# AE8SUPERSET_CM55_HE_View register map
Vendor: Alif Semiconductor; Series: E8; File version: 1.0
CPU: CM55 r1p0, selectable endian, MPU, FPU, double-precision FPU, DSP, VTOR, 8 interrupt priority bits, 1 SAU regions
Registers are 32-bit, read-write, reset 0x0 unless marked. A register's access mark holds for its fields unless they carry their own. Offsets are from the block's base; [hi:lo] are bit positions; lines under a group give offsets from that group; {n}, {i} and the like mark numbered series; 'fields as' and 'values as' point back to an identical list.

## LPUTIMER
Base 0x4300C000
Same registers: UTIMER 0x48000000
0x00 UTIMER_GLB_CNTR_START — Channels Global Counter Start Register
  [15:0] CHANNEL_NUM wo — Write 1 to start the associated channel counter.
0x04 UTIMER_GLB_CNTR_STOP — Channels Global Counter Stop Register
  [15:0] CHANNEL_NUM wo — Write 1 to stop the associated channel counter.
0x08 UTIMER_GLB_CNTR_CLEAR — Channels Global Counter Clear Register
  [15:0] CHANNEL_NUM wo — Write 1 to clear the associated channel counter.
0x0C UTIMER_GLB_CNTR_RUNNING ro — Channels Global Counter Running Status Register
  [15:0] CHANNEL_NUM — Real-time running status of each channel.
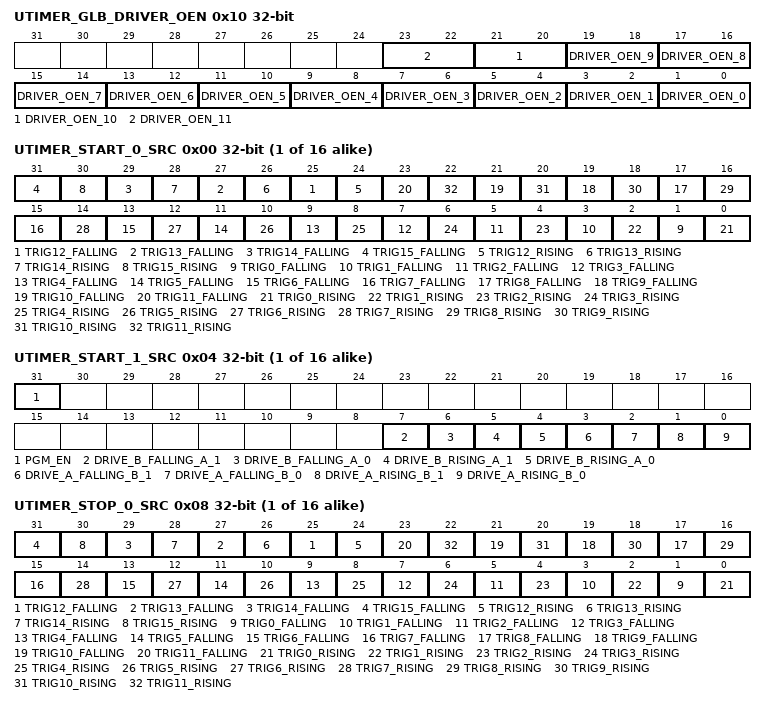
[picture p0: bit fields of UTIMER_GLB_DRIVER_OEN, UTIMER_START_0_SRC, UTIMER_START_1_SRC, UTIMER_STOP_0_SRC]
0x10 UTIMER_GLB_DRIVER_OEN — Channels Driver Output Enable Register
  [2n+1:2n] DRIVER_OEN_{n} (n=0..11) — Channel {n} active low output enable controls for driver A and B. B is the upper bit, A is the lower bit.
0x20 UTIMER_GLB_CLOCK_ENABLE — Channels Clock Enable Register
  [15:0] CHANNEL_NUM — Clock control for each channel.
{0x1000+0x1000*i} UTIMER_CHANNEL_CFG[{i}] (i=0..15) group
  0x00 UTIMER_START_0_SRC — Channel (n) Counter Start Source 0 Register
    [2n+1] TRIG{n}_FALLING (n=12..15) — For UTIMER channels: Falling edge of global trigger {n} causes counter to start. For QEC channels: Reserved, not used.
    [2n] TRIG{n}_RISING (n=12..15) — For UTIMER channels: Rising edge of global trigger {n} causes counter to start. For QEC channels: Reserved, not used.
    [2n+1] TRIG{n}_FALLING (n=0..11) — For UTIMER channels: Falling edge of global trigger {n} causes counter to start. For QEC channels: Falling edge of QEC_TRIGGER{n} causes counter to start.
    [2n] TRIG{n}_RISING (n=0..11) — For UTIMER channels: Rising edge of global trigger {n} causes counter to start. For QEC channels: Rising edge of QEC_TRIGGER{n} causes counter to start.
  0x04 UTIMER_START_1_SRC — Channel (n) Counter Start Source 1 Register
    [31] PGM_EN — Programatic Start Enabled:
      0=Global programmatic start is disabled; 1=Global programmatic start is enabled (only for start, stop, and clear)
    [7] DRIVE_B_FALLING_A_1 — For this channel, channel input B is falling and channel input A = 1 causes counter to start.
    [6] DRIVE_B_FALLING_A_0 — For this channel, channel input B is falling and channel input A = 0 causes counter to start.
    [5] DRIVE_B_RISING_A_1 — For this channel, channel input B is rising and channel input A = 1 causes counter to start.
    [4] DRIVE_B_RISING_A_0 — For this channel, channel input B is rising and channel input A = 0 causes counter to start.
    [3] DRIVE_A_FALLING_B_1 — For this channel, channel input A is falling and channel input B = 1 causes counter to start.
    [2] DRIVE_A_FALLING_B_0 — For this channel, channel input A is falling and channel input B = 0 causes counter to start.
    [1] DRIVE_A_RISING_B_1 — For this channel, channel input A is rising and channel input B = 1 causes counter to start.
    [0] DRIVE_A_RISING_B_0 — For this channel, channel input A is rising and channel input B = 0 causes counter to start.
  0x08 UTIMER_STOP_0_SRC — Channel (n) Counter Stop Source 0 Register
    [2n+1] TRIG{n}_FALLING (n=12..15) — For UTIMER channels: Falling edge of global trigger {n} causes counter to stop. For QEC channels: Reserved, not used.
    [2n] TRIG{n}_RISING (n=12..15) — For UTIMER channels: Rising edge of global trigger {n} causes counter to stop. For QEC channels: Reserved, not used.
    [2n+1] TRIG{n}_FALLING (n=0..11) — For UTIMER channels: Falling edge of global trigger {n} causes counter to stop. For QEC channels: Falling edge of QEC_TRIGGER{n} causes counter to stop.
    [2n] TRIG{n}_RISING (n=0..11) — For UTIMER channels: Rising edge of global trigger {n} causes counter to stop. For QEC channels: Rising edge of QEC_TRIGGER{n} causes counter to stop.
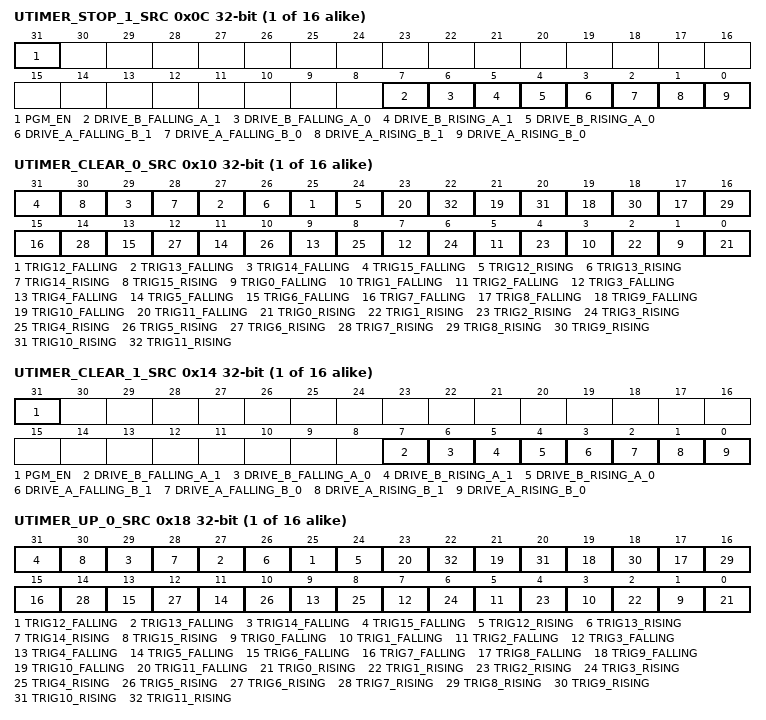
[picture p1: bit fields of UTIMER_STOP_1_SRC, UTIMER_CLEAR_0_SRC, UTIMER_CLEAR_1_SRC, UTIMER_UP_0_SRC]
  0x0C UTIMER_STOP_1_SRC — Channel (n) Counter Stop Source 1 Register
    [31] PGM_EN — Programatic Stop Enabled:
      0=Global programmatic stop is disabled; 1=Global programmatic stop is enabled (only for start, stop, and clear)
    [7] DRIVE_B_FALLING_A_1 — For this channel, channel input B is falling and channel input A = 1 causes counter to stop.
    [6] DRIVE_B_FALLING_A_0 — For this channel, channel input B is falling and channel input A = 0 causes counter to stop.
    [5] DRIVE_B_RISING_A_1 — For this channel, channel input B is rising and channel input A = 1 causes counter to stop.
    [4] DRIVE_B_RISING_A_0 — For this channel, channel input B is rising and channel input A = 0 causes counter to stop.
    [3] DRIVE_A_FALLING_B_1 — For this channel, channel input A is falling and channel input B = 1 causes counter to stop.
    [2] DRIVE_A_FALLING_B_0 — For this channel, channel input A is falling and channel input B = 0 causes counter to stop.
    [1] DRIVE_A_RISING_B_1 — For this channel, channel input A is rising and channel input B = 1 causes counter to stop.
    [0] DRIVE_A_RISING_B_0 — For this channel, channel input A is rising and channel input B = 0 causes counter to stop.
  0x10 UTIMER_CLEAR_0_SRC — Channel (n) Counter Clear Source 0 Register
    [2n+1] TRIG{n}_FALLING (n=12..15) — For UTIMER channels: Falling edge of global trigger {n} causes counter to clear. For QEC channels: Reserved, not used.
    [2n] TRIG{n}_RISING (n=12..15) — For UTIMER channels: Rising edge of global trigger {n} causes counter to clear. For QEC channels: Reserved, not used.
    [2n+1] TRIG{n}_FALLING (n=0..11) — For UTIMER channels: Falling edge of global trigger {n} causes counter to clear. For QEC channels: Falling edge of QEC_TRIGGER{n} causes counter to clear.
    [2n] TRIG{n}_RISING (n=0..11) — For UTIMER channels: Rising edge of global trigger {n} causes counter to clear. For QEC channels: Rising edge of QEC_TRIGGER{n} causes counter to clear.
  0x14 UTIMER_CLEAR_1_SRC — Channel (n) Counter Clear Source 1 Register
    [31] PGM_EN — Programmatic Clear Enabled:
      0=Global programmatic clear is disabled; 1=Global programmatic clear is enabled (only for start, stop, and clear)
    [7] DRIVE_B_FALLING_A_1 — For this channel, channel input B is falling and channel input A = 1 causes counter to clear.
    [6] DRIVE_B_FALLING_A_0 — For this channel, channel input B is falling and channel input A = 0 causes counter to clear.
    [5] DRIVE_B_RISING_A_1 — For this channel, channel input B is rising and channel input A = 1 causes counter to clear.
    [4] DRIVE_B_RISING_A_0 — For this channel, channel input B is rising and channel input A = 0 causes counter to clear.
    [3] DRIVE_A_FALLING_B_1 — For this channel, channel input A is falling and channel input B = 1 causes counter to clear.
    [2] DRIVE_A_FALLING_B_0 — For this channel, channel input A is falling and channel input B = 0 causes counter to clear.
    [1] DRIVE_A_RISING_B_1 — For this channel, channel input A is rising and channel input B = 1 causes counter to clear.
    [0] DRIVE_A_RISING_B_0 — For this channel, channel input A is rising and channel input B = 0 causes counter to clear.
  0x18 UTIMER_UP_0_SRC — Channel (n) Counter Up Count Source 0 Register
    [2n+1] TRIG{n}_FALLING (n=12..15) — For UTIMER channels: Falling edge of global trigger {n} causes counter to increment. For QEC channels: Reserved, not used.
    [2n] TRIG{n}_RISING (n=12..15) — For UTIMER channels: Rising edge of global trigger {n} causes counter to increment. For QEC channels: Reserved, not used.
    [2n+1] TRIG{n}_FALLING (n=0..11) — For UTIMER channels: Falling edge of global trigger {n} causes counter to increment. For QEC channels: Falling edge of QEC_TRIGGER{n} causes counter to increment.
    [2n] TRIG{n}_RISING (n=0..11) — For UTIMER channels: Rising edge of global trigger {n} causes counter to increment. For QEC channels: Rising edge of QEC_TRIGGER{n} causes counter to increment.
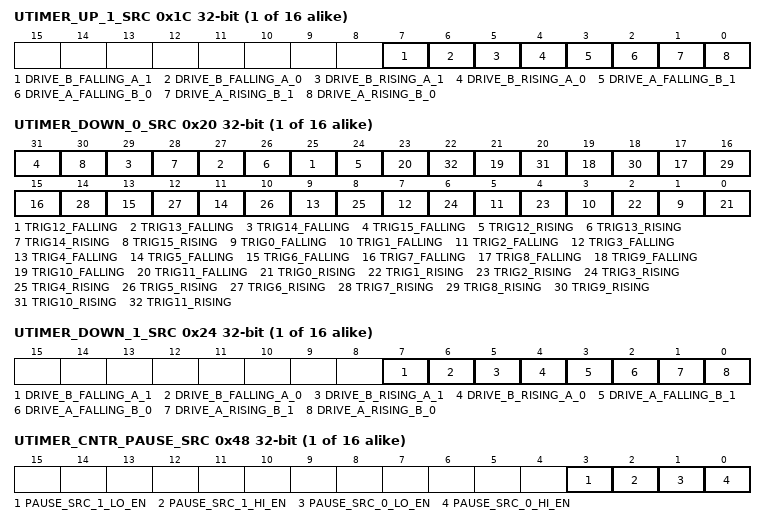
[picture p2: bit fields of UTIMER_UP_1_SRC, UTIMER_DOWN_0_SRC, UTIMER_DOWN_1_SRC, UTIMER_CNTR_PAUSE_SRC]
  0x1C UTIMER_UP_1_SRC — Channel (n) Counter Up Count Source 1 Register
    [7] DRIVE_B_FALLING_A_1 — For this channel, channel input B is falling and channel input A = 1 causes counter to increment.
    [6] DRIVE_B_FALLING_A_0 — For this channel, channel input B is falling and channel input A = 0 causes counter to increment.
    [5] DRIVE_B_RISING_A_1 — For this channel, channel input B is rising and channel input A = 1 causes counter to increment.
    [4] DRIVE_B_RISING_A_0 — For this channel, channel input B is rising and channel input A = 0 causes counter to increment.
    [3] DRIVE_A_FALLING_B_1 — For this channel, channel input A is falling and channel input B = 1 causes counter to increment.
    [2] DRIVE_A_FALLING_B_0 — For this channel, channel input A is falling and channel input B = 0 causes counter to increment.
    [1] DRIVE_A_RISING_B_1 — For this channel, channel input A is rising and channel input B = 1 causes counter to increment.
    [0] DRIVE_A_RISING_B_0 — For this channel, channel input A is rising and channel input B = 0 causes counter to increment.
  0x20 UTIMER_DOWN_0_SRC — Channel (n) Counter Down Count Source 0 Register
    [2n+1] TRIG{n}_FALLING (n=12..15) — For UTIMER channels: Falling edge of global trigger {n} causes counter to decrement. For QEC channels: Reserved, not used.
    [2n] TRIG{n}_RISING (n=12..15) — For UTIMER channels: Rising edge of global trigger {n} causes counter to decrement. For QEC channels: Reserved, not used.
    [2n+1] TRIG{n}_FALLING (n=0..11) — For UTIMER channels: Falling edge of global trigger {n} causes counter to decrement. For QEC channels: Falling edge of QEC_TRIGGER{n} causes counter to decrement.
    [2n] TRIG{n}_RISING (n=0..11) — For UTIMER channels: Rising edge of global trigger {n} causes counter to decrement. For QEC channels: Rising edge of QEC_TRIGGER{n} causes counter to decrement.
  0x24 UTIMER_DOWN_1_SRC — Channel (n) Counter Down Count Source 1 Register
    [7] DRIVE_B_FALLING_A_1 — For this channel, channel input B is falling and channel input A = 1 causes counter to decrement.
    [6] DRIVE_B_FALLING_A_0 — For this channel, channel input B is falling and channel input A = 0 causes counter to decrement.
    [5] DRIVE_B_RISING_A_1 — For this channel, channel input B is rising and channel input A = 1 causes counter to decrement.
    [4] DRIVE_B_RISING_A_0 — For this channel, channel input B is rising and channel input A = 0 causes counter to decrement.
    [3] DRIVE_A_FALLING_B_1 — For this channel, channel input A is falling and channel input B = 1 causes counter to decrement.
    [2] DRIVE_A_FALLING_B_0 — For this channel, channel input A is falling and channel input B = 0 causes counter to decrement.
    [1] DRIVE_A_RISING_B_1 — For this channel, channel input A is rising and channel input B = 1 causes counter to decrement.
    [0] DRIVE_A_RISING_B_0 — For this channel, channel input A is rising and channel input B = 0 causes counter to decrement.
  0x28 UTIMER_TRIG_CAPTURE_SRC_A_0 — Channel (n) Trigger Capture Source A 0 Register
    [31:0] TRIG_CAPTURE_SRC_A — Capture the counter value, when channel input A is the source (decoding is the same as in the UTIMERn_START_0_SRC register).
  0x2C UTIMER_TRIG_CAPTURE_SRC_A_1 — Channel (n) Trigger Capture Source A 1 Register
    [31:0] TRIG_CAPTURE_SRC_A — Capture the counter value, when channel input A is the source (decoding is the same as in the UTIMERn_START_1_SRC register).
  0x30 UTIMER_TRIG_CAPTURE_SRC_B_0 — Channel (n) Trigger Capture Source B 0 Register
    [31:0] TRIG_CAPTURE_SRC_B — Capture the counter value, when channel input B is the source (decoding is the same as in the UTIMERn_START_0_SRC register).
  0x34 UTIMER_TRIG_CAPTURE_SRC_B_1 — Channel (n) Trigger Capture Source B 1 Register
    [31:0] TRIG_CAPTURE_SRC_B — Capture the counter value, when channel input A is the source (decoding is the same as in the UTIMERn_START_1_SRC register).
  0x38 UTIMER_DMA_CLEAR_SRC_A_0 — Channel (n) DMA Clear Source A 0 Register
    [31:0] DMA_CLEAR_SRC_A — Clear DMA when driver A is the source (decoding is the same as in the UTIMERn_START_0_SRC register).
  0x3C UTIMER_DMA_CLEAR_SRC_A_1 — Channel (n) DMA Clear Source A 1 Register
    [31:0] DMA_CLEAR_SRC_A — Clear DMA when driver A is the source (decoding is the same as in the UTIMERn_START_1_SRC register).
  0x40 UTIMER_DMA_CLEAR_SRC_B_0 — Channel (n) DMA Clear Source B 0 Register
    [31:0] DMA_CLEAR_SRC_B — Clear DMA when driver B is the source (decoding is the same as in the UTIMERn_START_0_SRC register).
  0x44 UTIMER_DMA_CLEAR_SRC_B_1 — Channel (n) DMA Clear Source B 1 Register
    [31:0] DMA_CLEAR_SRC_B — Clear DMA when driver B is the source (decoding is the same as in the UTIMERn_START_1_SRC register).
  0x48 UTIMER_CNTR_PAUSE_SRC — Channel (n) Counter Pause Source Register
    [3] PAUSE_SRC_1_LO_EN — While PAUSE_TRIGGER[1] = 0x0, pause the channel counter.
    [2] PAUSE_SRC_1_HI_EN — While PAUSE_TRIGGER[1] = 0x1, pause the channel counter.
    [1] PAUSE_SRC_0_LO_EN — While PAUSE_TRIGGER[0] = 0x0, pause the channel counter.
    [0] PAUSE_SRC_0_HI_EN — While PAUSE_TRIGGER[0] = 0x1, pause the channel counter.
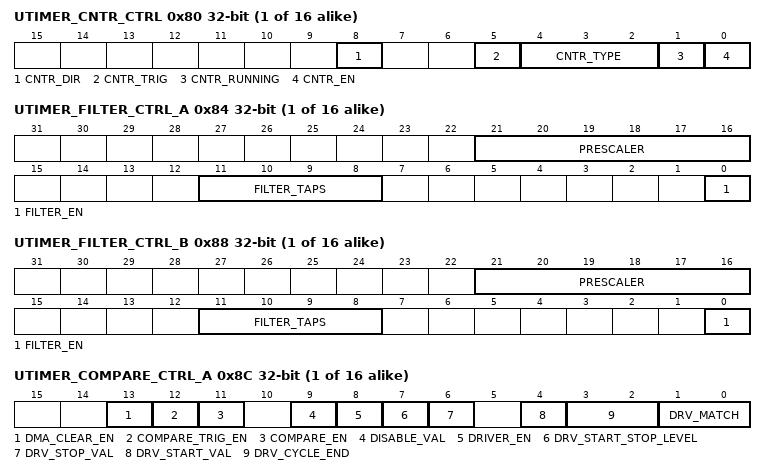
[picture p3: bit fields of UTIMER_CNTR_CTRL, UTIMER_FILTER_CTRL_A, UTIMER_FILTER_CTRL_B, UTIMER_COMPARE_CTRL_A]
  0x80 UTIMER_CNTR_CTRL — Channel (n) Counter Control Register
    [8] CNTR_DIR — Counter Direction: Note: For triangle counter, this will be the direction at a start event Note: If the direction is changed while the counter is running, it will take effect at the next over/underrun. Changes during triangle wave have no effect.
      0=Up; 1=Down
    [5] CNTR_TRIG — Set this bit if incrementing or decrementing the counter via triggers.
      0=Not in trigger based increment/decrement mode; 1=Trigger based increment/decrement mode
    [4:2] CNTR_TYPE — Counter Type:
      0=Sawtooth; 1=Sawtooth one shot; 4=Triangle; 6=Triangle one shot
    [1] CNTR_RUNNING — Counter Running: Note: Writing this bit have no effect.
      0=Count operation is stopped; 1=Count operation is running
    [0] CNTR_EN — Counter Enable:
      0=Counter is disabled; 1=Counter is enabled
  0x84 UTIMER_FILTER_CTRL_A — Channel (n) Filter Control A Register
    [21:16] PRESCALER — Prescaler function. Allows the input A to be sampled periodically according to the programmed value. For example, if programmed to 0x10, the input A is sampled every 16 clocks before entering the filter taps.
      0=Input A is sampled every clock before entering the filter taps; 1=Input A is sampled every clock before entering the filter taps; {v}=Input A is sampled periodically according to this value (v=2..63)
    [11:8] FILTER_TAPS — Number of filter taps.
    [0] FILTER_EN — Enable the filtering function.
  0x88 UTIMER_FILTER_CTRL_B — Channel (n) Filter Control B Register
    [21:16] PRESCALER — Prescaler function. Allows the input B to be sampled periodically according to the programmed value. For example, if programmed to 0x10, the input B is sampled every 16 clocks before entering the filter taps.
      0=Input B is sampled every clock before entering the filter taps; 1=Input B is sampled every clock before entering the filter taps; {v}=Input B is sampled periodically according to this value (v=2..63)
    [11:8] FILTER_TAPS — Number of filter taps.
    [0] FILTER_EN — Enable the filtering function.
  0x8C UTIMER_COMPARE_CTRL_A — Channel (n) Compare Control A Register
    [13] DMA_CLEAR_EN
      0=Disable DMA_CLEAR function; 1=Enable DMA_CLEAR function
    [12] COMPARE_TRIG_EN — Enable compare match for trigger input: Note: Only enable if desire compare function during trigger driven counting.
      0=Compare match when trigger count disabled; 1=Compare match when trigger count enabled
    [11] COMPARE_EN — Enable compare match:
      0=Compare match is disabled; 1=Compare match is enabled
    [9] DISABLE_VAL — Driver value when output is disabled via bit [8] of this register.
    [8] DRIVER_EN — Driver output enable.
      0=Driver output is disabled, will take value at bit [9] of this register; 1=Driver output is controlled by compare logic
    [7] DRV_START_STOP_LEVEL — Driver output level at start or stop:
      0=Driver output at start or stop reflects value at bit [4] and bit [6] of this register; 1=Driver output at start or stop is retained
    [6] DRV_STOP_VAL — Driver value when counting stops.
    [4] DRV_START_VAL — Driver value when counting starts.
    [3:2] DRV_CYCLE_END — Driver value at cycle end:
      0=Driver value retained at cycle end; 1=Driver value is 0x0 at cycle end; 2=Driver value is 0x1 at cycle end; 3=Driver value toggles at cycle end
    [1:0] DRV_MATCH — Driver A value at compare match:
      0=Driver value retained at compare match; 1=Driver value is 0x0 at compare match; 2=Driver value is 0x1 at compare match; 3=Driver value toggles at compare match
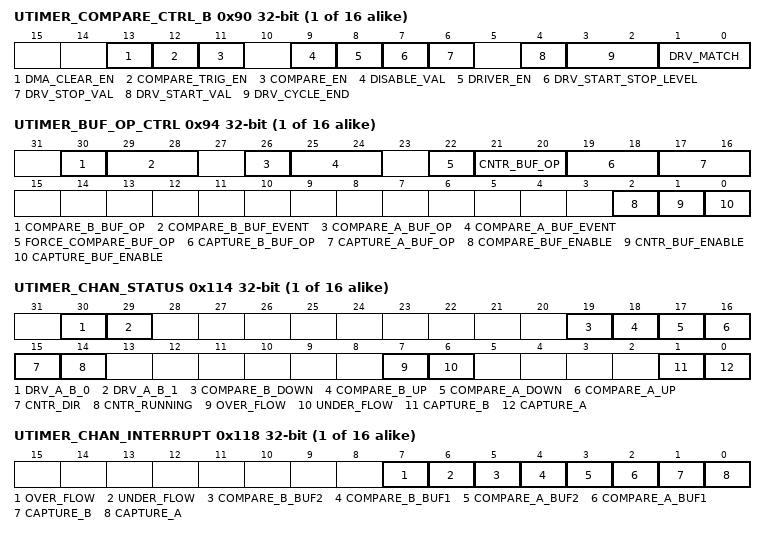
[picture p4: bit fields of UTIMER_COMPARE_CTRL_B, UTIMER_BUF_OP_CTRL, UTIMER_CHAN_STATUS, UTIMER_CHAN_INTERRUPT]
  0x90 UTIMER_COMPARE_CTRL_B — Channel (n) Compare Control B Register
    [13] DMA_CLEAR_EN
      0=Disable DMA_CLEAR function; 1=Enable DMA_CLEAR function
    [12] COMPARE_TRIG_EN — Enable compare match for trigger input: Note: Only enable if desire compare function during trigger driven counting.
      values as UTIMER_CHANNEL_CFG[0].UTIMER_COMPARE_CTRL_A.COMPARE_TRIG_EN
    [11] COMPARE_EN — Enable compare match:
      0=Compare match is disabled; 1=Compare match is enabled
    [9] DISABLE_VAL — Driver value when output is disabled via bit [8] of this register.
    [8] DRIVER_EN — Driver output enable.
      values as UTIMER_CHANNEL_CFG[0].UTIMER_COMPARE_CTRL_A.DRIVER_EN
    [7] DRV_START_STOP_LEVEL — Driver output level at start or stop:
      values as UTIMER_CHANNEL_CFG[0].UTIMER_COMPARE_CTRL_A.DRV_START_STOP_LEVEL
    [6] DRV_STOP_VAL — Driver value when counting stops.
    [4] DRV_START_VAL — Driver value when counting starts.
    [3:2] DRV_CYCLE_END — Driver value at cycle end:
      values as UTIMER_CHANNEL_CFG[0].UTIMER_COMPARE_CTRL_A.DRV_CYCLE_END
    [1:0] DRV_MATCH — Driver B value at compare match:
      values as UTIMER_CHANNEL_CFG[0].UTIMER_COMPARE_CTRL_A.DRV_MATCH
  0x94 UTIMER_BUF_OP_CTRL — Channel (n) Buffer Operation Control Register
    [30] COMPARE_B_BUF_OP
      0=Single buffer operation; 1=Double buffer operation
    [29:28] COMPARE_B_BUF_EVENT — For triangle wave: 0x0: No transfer (except triangle one shot) 0x1: Transfer at crest 0x2: Transfer at trough 0x3: Transfer at both crest and trough For sawtooth wave: 0x0: No transfer (except sawtooth one shot) Any other value: transfer at overflow or underflow (depends on direction)
    [26] COMPARE_A_BUF_OP — Buffer operation at compare on driver A:
      0=Single buffer operation; 1=Double buffer operation
    [25:24] COMPARE_A_BUF_EVENT — For triangle wave: 0x0: No transfer (except triangle one shot) 0x1: Transfer at crest 0x2: Transfer at trough 0x3: Transfer at both crest and trough For sawtooth wave: 0x0: No transfer (except sawtooth one shot) Any other value: transfer at overflow or underflow (depends on direction)
    [22] FORCE_COMPARE_BUF_OP — Writing 1 forces buffer operation of UTIMERn_COMPARE_A and UTIMERn_COMPARE_B registers for one shot modes. For more information, see the explanation on fixed buffering in UTIMER Buffers, including UTIMER Fixed Buffering Block Diagram.
    [21:20] CNTR_BUF_OP — Buffer operation is at overflow/underflow (for triangle wave, only underflow):
      0=No buffer operation; 1=Single buffer operation; 2=Double buffer operation
    [19:18] CAPTURE_B_BUF_OP — Buffer operation at capture on driver B:
      values as CNTR_BUF_OP
    [17:16] CAPTURE_A_BUF_OP — Buffer operation at capture on driver A:
      values as CNTR_BUF_OP
    [2] COMPARE_BUF_ENABLE — Enable buffer operation at compare:
      0=Buffer operation at compare is disabled; 1=Buffer operation at compare is enabled
    [1] CNTR_BUF_ENABLE — Enable counter buffer:
      0=Counter buffer operation is disabled; 1=Counter buffer operation is enabled
    [0] CAPTURE_BUF_ENABLE — Enable buffer operation at capture:
      0=Buffer operation at capture is disabled; 1=Buffer operation at capture is enabled
  0xA0 UTIMER_CNTR — Channel (n) Counter Register
    [31:0] CNTR — Write or read value of the counter. Note: Value must be written only when the counter is stopped.
  0xA4 UTIMER_CNTR_PTR — Channel (n) Counter Pointer Register
    [31:0] CNTR_PTR — Counter maximum value.
  0xA8 UTIMER_CNTR_PTR_BUF1 — Channel (n) Counter Pointer Buffer 1 Register
    [31:0] CNTR_PTR_BUF1 — Counter pointer for buffer 1.
  0xAC UTIMER_CNTR_PTR_BUF2 — Channel (n) Counter Pointer Buffer 2 Register
    [31:0] CNTR_PTR_BUF2 — Counter pointer for buffer 2.
  0xB0 UTIMER_CAPTURE_A — Channel (n) Capture A Register
    [31:0] CAPTURE_A — Top register for capture operation on driver A.
  0xB4 UTIMER_CAPTURE_A_BUF1 — Channel (n) Capture A Buffer 1 Register
    [31:0] CAPTURE_A_BUF1 — Value of buffer 1 for capture operation on driver A.
  0xB8 UTIMER_CAPTURE_A_BUF2 — Channel (n) Capture A Buffer 2 Register
    [31:0] CAPTURE_A_BUF2 — Value of buffer 2 for capture operation on driver A.
  0xC0 UTIMER_CAPTURE_B — Channel (n) Capture B Register
    [31:0] CAPTURE_B — Top register for capture operation on driver B.
  0xC4 UTIMER_CAPTURE_B_BUF1 — Channel (n) Capture B Buffer 1 Register
    [31:0] CAPTURE_B_BUF1 — Value of buffer 1 for capture operation on driver B.
  0xC8 UTIMER_CAPTURE_B_BUF2 — Channel (n) Capture B Buffer 2 Register
    [31:0] CAPTURE_B_BUF2 — Value of buffer 2 for capture operation on driver B.
  0xD0 UTIMER_COMPARE_A — Channel (n) Compare A Register
    [31:0] COMPARE_A — Top register for compare operation on driver A.
  0xD4 UTIMER_COMPARE_A_BUF1 — Channel (n) Compare A Buffer 1 Register
    [31:0] COMPARE_A_BUF1 — Value of buffer 1 for compare operation on driver A.
  0xD8 UTIMER_COMPARE_A_BUF2 — Channel (n) Compare A Buffer 2 Register
    [31:0] COMPARE_A_BUF2 — Value of buffer 2 for compare operation on driver A.
  0xE0 UTIMER_COMPARE_B — Channel (n) Compare B Register
    [31:0] COMPARE_B — Top register for compare operation on driver B.
  0xE4 UTIMER_COMPARE_B_BUF1 — Channel (n) Compare B Buffer 1 Register
    [31:0] COMPARE_B_BUF1 — Value of buffer 1 for compare operation on driver B.
  0xE8 UTIMER_COMPARE_B_BUF2 — Channel (n) Compare B Buffer 2 Register
    [31:0] COMPARE_B_BUF2 — Value of buffer 2 for compare operation on driver B.
  0xF0 UTIMER_DT_UP — Channel (n) Dead-time Up Register
    [31:0] DT_UP — Dead-time in counter direction up.
  0xF4 UTIMER_DT_UP_BUF1 — Channel (n) Dead-time Up Buffer 1 Register
    [31:0] DT_UP_BUF1 — Dead-time in counter direction up for buffer 1.
  0xF8 UTIMER_DT_DOWN — Channel (n) Dead-time Down Register
    [31:0] DT_DOWN — Dead-time in counter direction down.
  0xFC UTIMER_DT_DOWN_BUF1 — Channel (n) Dead-time Down Buffer 1 Register
    [31:0] DT_DOWN_BUF1 — Dead-time in counter direction down for buffer 1.
  0x114 UTIMER_CHAN_STATUS — Channel (n) Status Register
    [30] DRV_A_B_0 — Drivers A and B are both 0. Note: This bit contains the current status.
    [29] DRV_A_B_1 — Drivers A and B are both 1. Note: This bit contains the current status.
    [19] COMPARE_B_DOWN — Compare on driver B during down counting. Note: This status bit is only valid when the counter is free-running.
    [18] COMPARE_B_UP — Compare on driver B during up counting. Note: This status bit is only valid when the counter is free-running.
    [17] COMPARE_A_DOWN — Compare on driver A during down counting. Note: This status bit is only valid when the counter is free-running.
    [16] COMPARE_A_UP — Compare on driver A during up counting. Note: This status bit is only valid when the counter is free-running.
    [15] CNTR_DIR — Counter Direction: Note: This bit contains the current status, only valid if counter is running.
      0=Counter is downward; 1=Counter is upward
    [14] CNTR_RUNNING — Counter running status: Note: This bit contains the current status.
      0=Counter is not running; 1=Counter is running
    [7] OVER_FLOW — An overflow (or crest) had occurred.
    [6] UNDER_FLOW — An underflow (or trough) had occurred.
    [1] CAPTURE_B — Capture event on driver B occurred due to a trigger.
    [0] CAPTURE_A — Capture event on driver A occurred due to a trigger.
  0x118 UTIMER_CHAN_INTERRUPT wo — Channel (n) Interrupt Control Register
    [7] OVER_FLOW — An overflow event had occurred. Write 1 to clear bit.
    [6] UNDER_FLOW — An underflow event had occurred. Write 1 to clear bit.
    [5] COMPARE_B_BUF2 — Compare of COMPARE_B_BUF2. Write 1 to clear bit.
    [4] COMPARE_B_BUF1 — Compare of COMPARE_B_BUF1. Write 1 to clear bit.
    [3] COMPARE_A_BUF2 — Compare of COMPARE_A_BUF2. Write 1 to clear bit.
    [2] COMPARE_A_BUF1 — Compare of COMPARE_A_BUF1. Write 1 to clear bit.
    [1] CAPTURE_B — Capture B or compare B event had occurred. Write 1 to clear bit.
    [0] CAPTURE_A — Capture A or compare A event had occurred. Write 1 to clear bit.
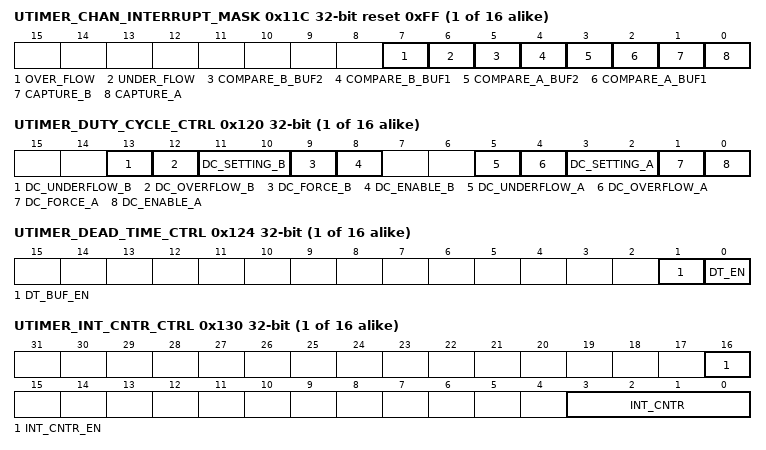
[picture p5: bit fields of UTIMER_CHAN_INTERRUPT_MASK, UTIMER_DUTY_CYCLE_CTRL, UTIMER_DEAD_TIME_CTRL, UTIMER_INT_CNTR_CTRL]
  0x11C UTIMER_CHAN_INTERRUPT_MASK reset 0xFF — Channel (n) Interrupt Mask Register
    [7] OVER_FLOW — Mask for channel interrupts.
    [6] UNDER_FLOW — Mask for channel interrupts.
    [5] COMPARE_B_BUF2 — Mask for channel interrupts.
    [4] COMPARE_B_BUF1 — Mask for channel interrupts.
    [3] COMPARE_A_BUF2 — Mask for channel interrupts.
    [2] COMPARE_A_BUF1 — Mask for channel interrupts.
    [1] CAPTURE_B — Mask for channel interrupts.
    [0] CAPTURE_A — Mask for channel interrupts.
  0x120 UTIMER_DUTY_CYCLE_CTRL — Channel (n) Duty Cycle Control Register
    [13] DC_UNDERFLOW_B — Apply duty cycle at underflow of driver B.
    [12] DC_OVERFLOW_B — Apply duty cycle at overflow of driver B.
    [11:10] DC_SETTING_B — Duty cycle setting for driver B:
      0=Compare match determines duty cycle (no masking); 1=Compare match determines duty cycle (no masking); 2=0% duty cycle; 3=100% duty cycle
    [9] DC_FORCE_B — Force duty cycle for output B at cycle start, reflecting the UTIMERn_DUTY_CYCLE_CTRL[DC_SETTING_B] bit field.
    [8] DC_ENABLE_B — Enable the duty cycle function for driver B.
    [5] DC_UNDERFLOW_A — Apply duty cycle at underflow of driver A.
    [4] DC_OVERFLOW_A — Apply duty cycle at overflow of driver A.
    [3:2] DC_SETTING_A — Duty cycle setting for driver A:
      values as DC_SETTING_B
    [1] DC_FORCE_A — Force duty cycle for output A at cycle start, reflecting the UTIMERn_DUTY_CYCLE_CTRL[DC_SETTING_A] bit field.
    [0] DC_ENABLE_A — Enable the duty cycle function for driver A.
  0x124 UTIMER_DEAD_TIME_CTRL — Channel (n) Dead-time Control Register
    [1] DT_BUF_EN — Enable dead-time buffer operation.
    [0] DT_EN — Dead-time enable.
  0x130 UTIMER_INT_CNTR_CTRL — Channel (n) Interrupt Counter Control Register
    [16] INT_CNTR_EN — Enables the counting of overflow or underflow events.
    [3:0] INT_CNTR — Interrupt counter. This number of overflow or underflow events must occur before the corresponding interrupt is triggered.
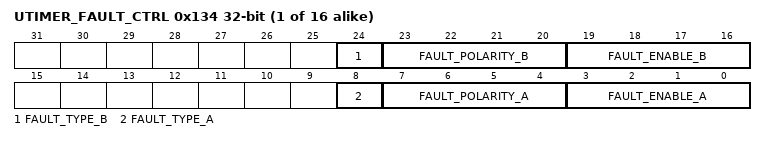
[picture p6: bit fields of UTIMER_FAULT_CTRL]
  0x134 UTIMER_FAULT_CTRL — Channel (n) Fault Control Register
    [24] FAULT_TYPE_B
      0=Will force output driver B low and keep low until overflow or underflow; 1=Will force output driver B low and keep low until a counter stop event is seen
    [23:20] FAULT_POLARITY_B — Bit enable to determine FAULT_TRIGGER[3-0] active polarity for output driver B.
      0=Will force output driver B low when associated FAULT_TRIGGER[3-0] is low; 1=Will force output driver B low when associated FAULT_TRIGGER[3-0] is high
    [19:16] FAULT_ENABLE_B — Bit enable to use FAULT_TRIGGER[3-0] to control channel output driver B.
      0=Associated FAULT_TRIGGER has no effect on output drivers; 1=Associated FAULT_TRIGGER active to control output drivers
    [8] FAULT_TYPE_A
      0=Will force output driver A low and keep low until overflow or underflow; 1=Will force output driver A low and keep low until a counter stop event is seen
    [7:4] FAULT_POLARITY_A — Bit enable to determine FAULT_TRIGGER[3-0] active polarity for output driver A
      0=Will force output driver A low when associated FAULT_TRIGGER[3-0] is low; 1=Will force output driver A low when associated FAULT_TRIGGER[3-0] is high
    [3:0] FAULT_ENABLE_A — Bit enable to use FAULT_TRIGGER[3-0] to control channel output driver A.
      values as FAULT_ENABLE_B
